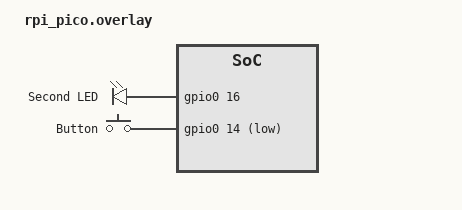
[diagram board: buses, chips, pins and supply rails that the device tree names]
/*
 * boards/rpi_pico.overlay: this application's changes to the Pico devicetree.
 *
 * Zephyr merges this file into the board's own description (boards/raspberrypi/rpi_pico/
 * rpi_pico.dts and the files it includes) before the C code is compiled. The result is in
 * build/zephyr/zephyr.dts. Nodes here are added to, or override, the nodes of the board.
 */
#include <zephyr/dt-bindings/gpio/gpio.h>

/ {
	/* The board already has a "leds" node with led0 on GP25. Adding a child adds an LED. */
	leds {
		led1: led_1 {
			gpios = <&gpio0 16 GPIO_ACTIVE_HIGH>;	/* GP16, high = on */
			label = "Second LED";
		};
	};

	/* The compatible string selects the binding in dts/bindings/input/vnd,user-button.yaml.
	 * Without a binding, Zephyr does not generate the GPIO_DT_SPEC for this node. No driver
	 * binds to it, so the button is read by polling in main.c. */
	buttons {
		user_button: button_0 {
			compatible = "vnd,user-button";
			gpios = <&gpio0 14 (GPIO_ACTIVE_LOW | GPIO_PULL_UP)>;	/* GP14, pressed = low */
			label = "Button";
		};
	};

	/* An alias is the name the C code uses. DT_ALIAS(led1) finds led1 without knowing its
	 * path, so moving the node later only changes this file. */
	aliases {
		led1 = &led1;
		sw0 = &user_button;
	};
};
